# INTC register map
Vendor: Texas Instruments
Peripheral module from a debugger description file (folder am335x).
Registers are 32-bit, access per field, no defined reset value unless marked. A register's access mark holds for its fields unless they carry their own. Offsets are as the file gives them; lines under a group give offsets from that group; [hi:lo] are bit positions; {n}, {i} and the like mark numbered series; 'fields as' and 'values as' point back to an identical list; <NAME> marks a mode.

## INTC
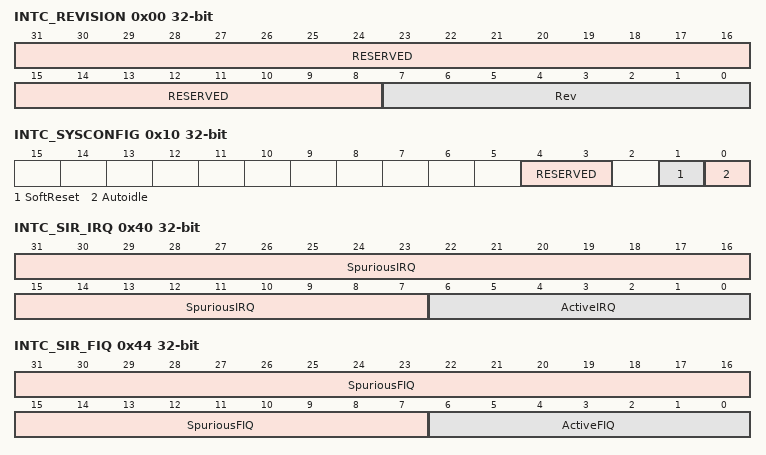
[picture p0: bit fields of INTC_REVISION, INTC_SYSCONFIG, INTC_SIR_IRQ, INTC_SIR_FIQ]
0x00 INTC_REVISION ro — This register contains the IP revision code
  [31:8] RESERVED — Reads returns 0
  [7:0] Rev — IP revision [7:4] Major revision [3:0] Minor revision Examples: 0x10 for 1.0, 0x21 for 2.1
0x10 INTC_SYSCONFIG — This register controls the various parameters of the OCP interface
  [4:3] RESERVED ro — Write 0's for future compatibility. Reads returns 0
  [1] SoftReset rw — Software reset. Set this bit to trigger a module reset. The bit is automatically reset by the hardware. During reads, it always returns 0.
    0=Always returns 0; 0=nofun_w (no functional effect); 1=never_r (never happens); 1=rstMode_w (The module is reset)
  [0] Autoidle rw — Internal OCP clock gating strategy
    0=clkfree (OCP clock is free running); 1=autoClkGate (Automatic OCP clock gating strategy is applied, bnased on the OCP interface activity)
0x14 INTC_SYSSTATUS ro — This register provides status information about the module
  [0] ResetDone — Internal reset monitoring
    0=rstOngoing (Internal module reset is on-going); 1=rstComp (Reset completed)
0x40 INTC_SIR_IRQ rw — This register supplies the currently active IRQ interrupt number.
  [31:7] SpuriousIRQ — Spurious IRQ flag
  [6:0] ActiveIRQ — Active IRQ number
0x44 INTC_SIR_FIQ ro — This register supplies the currently active FIQ interrupt number
  [31:7] SpuriousFIQ — Spurious FIQ flag
  [6:0] ActiveFIQ — Active FIQ number
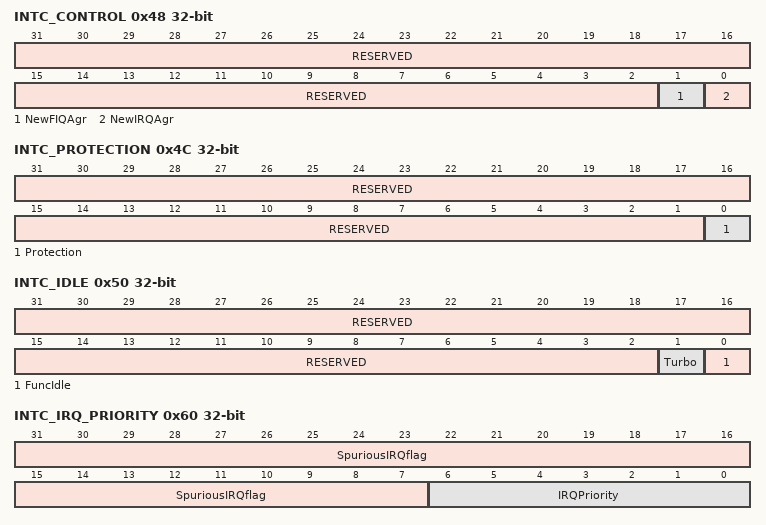
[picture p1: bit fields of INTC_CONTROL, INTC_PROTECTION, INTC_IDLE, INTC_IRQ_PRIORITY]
0x48 INTC_CONTROL — This register contains the new interrupt agreement bits
  [31:2] RESERVED ro — Write 0's for future compatibility. Reads returns 0
  [1] NewFIQAgr wo — Reset FIQ output and enable new FIQ generation
    0=nofun_w (no function effect); 1=NewFiq_w (Reset FIQ output and enable new FIQ generation)
  [0] NewIRQAgr wo — New IRQ generation
    0=nofun_w (no function effect); 1=NewIrq_w (Reset IRQ output and enable new IRQ generation)
0x4C INTC_PROTECTION — This register controls protection of the other registers. This register can only be accessed in priviledged mode, regardless of the curent value of the protection bit.
  [31:1] RESERVED ro — Write 0's for future compatibility. Reads returns 0
  [0] Protection rw — Protection mode
    0=ProtMDis (Protection mode disabled (default)); 1=ProtMEnb (Protection mode enabled. When enabled, only priviledged mode can access registers.)
0x50 INTC_IDLE — This register controls the clock auto-idle for the functional clock and the input synchronisers
  [31:2] RESERVED ro — Write 0's for future compatibility. Reads returns 0
  [1] Turbo rw — Input synchroniser clock auto-gating
    0=SyncFree (Input synchroniser clock is free running (default)); 1=SyncAuto (Input synchroniser clock is auto-gated based on interrupt input activity)
  [0] FuncIdle rw — Functional clock auto-idle mode
    0=FuncAuto (Functional clock gating strategy is applied (default)); 1=FuncFree (Functional clock is free-running)
0x60 INTC_IRQ_PRIORITY ro — This register supplies the currently active IRQ priority level
  [31:7] SpuriousIRQflag
  [6:0] IRQPriority — Current IRQ priority
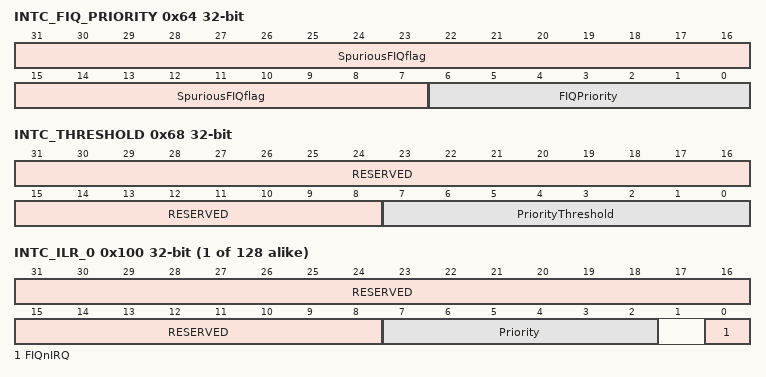
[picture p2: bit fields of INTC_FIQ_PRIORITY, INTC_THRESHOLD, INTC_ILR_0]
0x64 INTC_FIQ_PRIORITY ro — This register supplies the currently active FIQ priority level
  [31:7] SpuriousFIQflag
  [6:0] FIQPriority — Current FIQ priority
0x68 INTC_THRESHOLD — This register sets the priority threshold
  [31:8] RESERVED ro — Reads returns 0
  [7:0] PriorityThreshold rw — Priority threshold (used values 0x00-0x1f or 0x00-0x3f, 0xff disables the threshold).
{0x80+0x20*i} INTC_ITR{i} ro (i=0..3) — This register shows the raw interrupt input status before masking
  [31:0] Itr — Interrupt status before masking
{0x84+0x20*i} INTC_MIR{i} rw (i=0..3) — This register contains the interrupt mask
  [31:0] Mir — Interrupt mask
{0x88+0x20*i} INTC_MIR_CLEAR{i} wo (i=0..3) — This register is used to clear the interrupt mask bits.
  [31:0] MirClear — Write 1 clears the mask bit to 0, reads return 0
{0x8C+0x20*i} INTC_MIR_SET{i} wo (i=0..3) — This register is used to set the interrupt mask bits.
  [31:0] MirSet — Write 1 sets the mask bit to 1, reads return 0
{0x90+0x20*i} INTC_ISR_SET{i} rw (i=0..3) — This register is used to set the software interrupt bits. It is also used to read the currently active software interrupts.
  [31:0] IsrSet — Reads returns the currently active software interrupts, Write 1 sets the software interrupt bits to 1
{0x94+0x20*i} INTC_ISR_CLEAR{i} wo (i=0..3) — This register is used to clear the software interrupt bits
  [31:0] IsrClear — Write 1 clears the sofware interrupt bits to 0, reads return 0
{0x98+0x20*i} INTC_PENDING_IRQ{i} ro (i=0..3) — This register contains the IRQ status after masking
  [31:0] PendingIRQ — IRQ status after masking
{0x9C+0x20*i} INTC_PENDING_FIQ{i} ro (i=0..3) — This register contains the FIQ status after masking
  [31:0] PendingFIQ — FIQ status after masking
{0x100+4i} INTC_ILR_{i} (i=0..127) — The INTC_ILRx registers contain the priority for the interrupts and the FIQ/IRQ steering.
  [31:8] RESERVED ro — Write 0's for future compatibility. Reads returns 0
  [7:2] Priority rw — Interrupt priority
  [0] FIQnIRQ rw — Interrupt IRQ FiQ mapping
    0=IntIRQ (Interrupt is routed to IRQ.); 1=IntFIQ (Interrupt is routed to FIQ (this selection is reserved on GP devices).)
